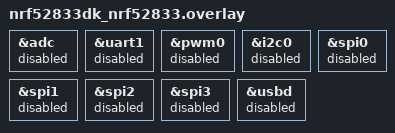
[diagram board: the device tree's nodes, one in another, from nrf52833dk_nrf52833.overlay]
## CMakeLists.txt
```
cmake_minimum_required(VERSION 3.20.0)
find_package(Zephyr REQUIRED HINTS $ENV{ZEPHYR_BASE})

project(thread-ftd)

target_sources(app PRIVATE src/main.c)
```

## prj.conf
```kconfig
# GPIO enable
CONFIG_GPIO=y

# nRF board library
CONFIG_DK_LIBRARY=y

# Generic networking options
CONFIG_NETWORKING=y

CONFIG_NET_L2_OPENTHREAD=y

# Enable OpenThread features set
CONFIG_OPENTHREAD_NORDIC_LIBRARY_MASTER=y

# Thread Network default parameters
CONFIG_OPENTHREAD_MANUAL_START=n

# Commissioning
CONFIG_OPENTHREAD_JOINER_AUTOSTART=y

# Network shell
CONFIG_SHELL=y
CONFIG_OPENTHREAD_SHELL=y
CONFIG_SHELL_ARGC_MAX=26
CONFIG_SHELL_CMD_BUFF_SIZE=416

CONFIG_MBEDTLS_SHA1_C=n
CONFIG_FPU=y

CONFIG_GPIO_SHELL=y

# Logging
CONFIG_NET_LOG=y
CONFIG_LOG=y
CONFIG_PRINTK=y
CONFIG_LOG_BACKEND_RTT=y
CONFIG_LOG_DEFAULT_LEVEL=3
```

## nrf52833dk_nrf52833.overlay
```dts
&adc {
	status = "disabled";
};
&uart1 {
	status = "disabled";
};
&pwm0 {
	status = "disabled";
};
&i2c0 {
	status = "disabled";
};
&spi0 {
	status = "disabled";
};
&spi1 {
	status = "disabled";
};
&spi2 {
	status = "disabled";
};
&spi3 {
	status = "disabled";
};
&usbd {
	status = "disabled";
};
```

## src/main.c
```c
#include <zephyr/kernel.h>
#include <dk_buttons_and_leds.h>
#include <openthread/thread.h>
#include <zephyr/net/openthread.h>
#include <zephyr/logging/log.h>
#include <stdbool.h>

bool is_connected;

#define THREAD_CONNECTION_LED   (DK_LED2)

LOG_MODULE_REGISTER(FTD, CONFIG_LOG_DEFAULT_LEVEL);

static void on_thread_state_changed(otChangedFlags flags,
                             struct openthread_context *ot_context,
                             void *user_data)
{
	if (flags & OT_CHANGED_THREAD_ROLE) 
    {
		switch (otThreadGetDeviceRole(ot_context->instance)) 
        {
            case OT_DEVICE_ROLE_CHILD:
            case OT_DEVICE_ROLE_ROUTER:
            case OT_DEVICE_ROLE_LEADER:
            is_connected = true;
            dk_set_led_on(THREAD_CONNECTION_LED);
            break;

            case OT_DEVICE_ROLE_DISABLED:
            case OT_DEVICE_ROLE_DETACHED:
            default:
            is_connected = false;
            dk_set_led_off(THREAD_CONNECTION_LED);
            break;
		}
	}
}

static struct openthread_state_changed_cb ot_state_chaged_cb = { .state_changed_cb =
									 on_thread_state_changed };

int main(void)
{
    int ret;

    if ( (ret = dk_leds_init()) != 0 )
    {
        LOG_ERR("Cannot init leds (error: %d)", ret);
		return ret;
    }

    if ( (ret = openthread_state_changed_cb_register(openthread_get_default_context(), &ot_state_chaged_cb)) != 0)
    {
        LOG_ERR("Unable to set openthread_state_changed_cb_register: %d", ret);
        return ret;
    }

    return 0;
}
```
